# SAM9X60D1G_SOM device description
Architecture: ARM926EJ-S; Family: SAM9; Series: SAM9X6
Registers are 32-bit, read-write, no defined reset value unless marked. A register's access mark holds for its fields unless they carry their own. Offsets are from the block's base; [hi:lo] are bit positions; {n}, {i} and the like mark numbered series.

## DBGU — Debug Unit
Instances: DBGU 0xFFFFF200
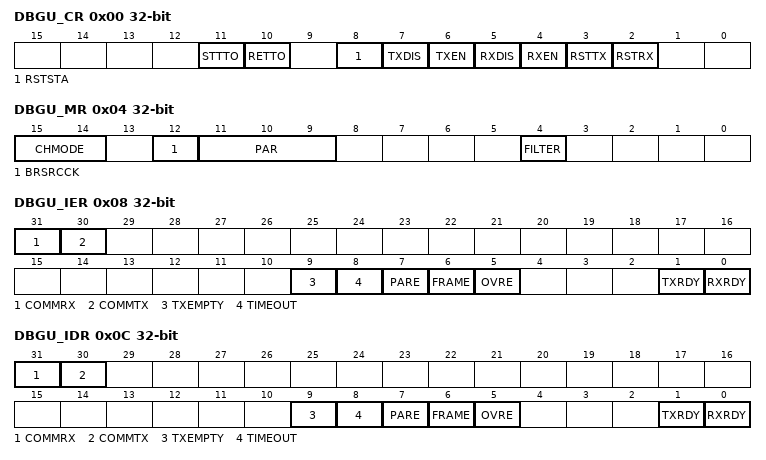
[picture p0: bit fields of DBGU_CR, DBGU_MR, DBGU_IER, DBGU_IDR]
0x00 DBGU_CR wo — Control Register
  [11] STTTO — Start Timeout
  [10] RETTO — Rearm Timeout
  [8] RSTSTA — Reset Status
  [7] TXDIS — Transmitter Disable
  [6] TXEN — Transmitter Enable
  [5] RXDIS — Receiver Disable
  [4] RXEN — Receiver Enable
  [3] RSTTX — Reset Transmitter
  [2] RSTRX — Reset Receiver
0x04 DBGU_MR — Mode Register
  [15:14] CHMODE — Channel Mode
    0=NORMAL (Normal mode); 1=AUTOMATIC (Automatic echo); 2=LOCAL_LOOPBACK; 3=REMOTE_LOOPBACK
  [12] BRSRCCK — Baud Rate Source Clock
    0=PERIPH_CLK (The baud rate is driven by the peripheral clock); 1=GCLK (The baud rate is driven by a PMC-programmable clock GCLK (see section Power Management Controller (PMC)).)
  [11:9] PAR — Parity Type
    0=EVEN (Even Parity); 1=ODD (Odd Parity); 2=SPACE (Space: parity forced to 0); 3=MARK (Mark: parity forced to 1); 4=NO (No parity)
  [4] FILTER — Receiver Digital Filter
    0=DISABLED (DBGU does not filter the receive line.); 1=ENABLED (DBGU filters the receive line using a three-sample filter (16x-bit clock) (2 over 3 majority).)
0x08 DBGU_IER wo — Interrupt Enable Register
  [31] COMMRX — Enable COMMRX (from ARM) Interrupt
  [30] COMMTX — Enable COMMTX (from ARM) Interrupt
  [9] TXEMPTY — Enable TXEMPTY Interrupt
  [8] TIMEOUT — Enable Timeout Interrupt
  [7] PARE — Enable Parity Error Interrupt
  [6] FRAME — Enable Framing Error Interrupt
  [5] OVRE — Enable Overrun Error Interrupt
  [1] TXRDY — Enable TXRDY Interrupt
  [0] RXRDY — Enable RXRDY Interrupt
0x0C DBGU_IDR wo — Interrupt Disable Register
  [31] COMMRX — Disable COMMRX (from ARM) Interrupt
  [30] COMMTX — Disable COMMTX (from ARM) Interrupt
  [9] TXEMPTY — Disable TXEMPTY Interrupt
  [8] TIMEOUT — Disable Timeout Interrupt
  [7] PARE — Disable Parity Error Interrupt
  [6] FRAME — Disable Framing Error Interrupt
  [5] OVRE — Disable Overrun Error Interrupt
  [1] TXRDY — Disable TXRDY Interrupt
  [0] RXRDY — Disable RXRDY Interrupt
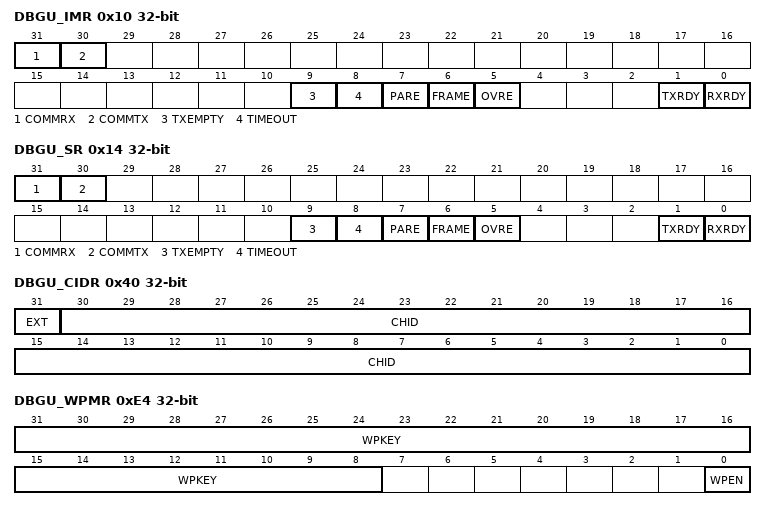
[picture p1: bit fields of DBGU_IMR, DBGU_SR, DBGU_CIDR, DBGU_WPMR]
0x10 DBGU_IMR ro — Interrupt Mask Register
  [31] COMMRX — Mask COMMRX (from ARM) Interrupt
  [30] COMMTX — Mask COMMTX (from ARM) Interrupt
  [9] TXEMPTY — Mask TXEMPTY Interrupt
  [8] TIMEOUT — Mask Timeout Interrupt
  [7] PARE — Mask Parity Error Interrupt
  [6] FRAME — Mask Framing Error Interrupt
  [5] OVRE — Mask Overrun Error Interrupt
  [1] TXRDY — Disable TXRDY Interrupt
  [0] RXRDY — Mask RXRDY Interrupt
0x14 DBGU_SR ro — Status Register
  [31] COMMRX — Debug Communication Channel Read Status
  [30] COMMTX — Debug Communication Channel Write Status
  [9] TXEMPTY — Transmitter Empty
  [8] TIMEOUT — Receiver Timeout
  [7] PARE — Parity Error
  [6] FRAME — Framing Error
  [5] OVRE — Overrun Error
  [1] TXRDY — Transmitter Ready
  [0] RXRDY — Receiver Ready
0x18 DBGU_RHR ro — Receive Holding Register
  [7:0] RXCHR — Received Character
0x1C DBGU_THR wo — Transmit Holding Register
  [7:0] TXCHR — Character to be Transmitted
0x20 DBGU_BRGR — Baud Rate Generator Register
  [15:0] CD — Clock Divisor
0x28 DBGU_RTOR — Receiver Timeout Register
  [7:0] TO — Timeout Value
0x40 DBGU_CIDR ro — Chip ID Register
  [31] EXT — Extension Flag
  [30:0] CHID — Chip ID Value
0x44 DBGU_EXID ro — Chip ID Extension Register
  [31:0] EXID — Chip ID Extension
0x48 DBGU_FNR — Force NTRST Register
  [0] FNTRST — Force NTRST
0xE4 DBGU_WPMR — Write Protection Mode Register
  [31:8] WPKEY — Write Protection Key
    0x554152=PASSWD (Writing any other value in this field aborts the write operation. Always reads as 0.)
  [0] WPEN — Write Protection Enable

## GPBR — General Purpose Backup Registers
Instances: GPBR 0xFFFFFE60
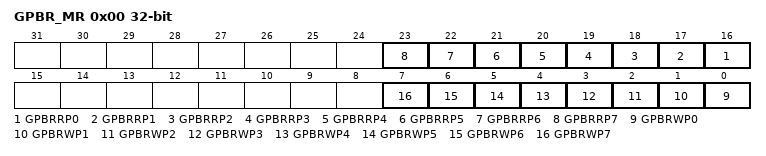
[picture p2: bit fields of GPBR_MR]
0x00 GPBR_MR — GPBR Mode Register
  [n+16] GPBRRP{n} (n=0..7) — GPBRx Read Protection
  [n] GPBRWP{n} (n=0..7) — GPBRx Write Protection
0x04 GPBR_FCLR — GPBR Full Clear Register
  [0] FCLR — Full Clear Enable
{0x8+4i} SYS_GPBR[{i}] (i=0..7) — General Purpose Backup Register
  [31:0] GPBR_VALUE — Value of SYS_GPBR x
